AUTOSAR XML (schema 4-2-2)
package /ETAS_BIP_STACKM/SwComponentTypes
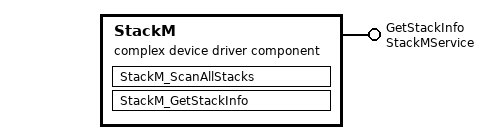
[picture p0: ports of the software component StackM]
  complex device driver sw component type StackM
    provide port GetStackInfo: provided-interface=StackMService
    behavior IntBeh_StackM
      operation invoked event OIE_GetStackInfo: start-on-event=StackM_GetStackInfo, operation=GetStackInfo.GetStackInfo
      runnable StackM_ScanAllStacks
      runnable StackM_GetStackInfo
package /ETAS_BIP_STACKM/SwcImplementations
  swc implementation Impl_StackM: programming-language=C, sw-version=2.0.0, swc-bsw-mapping=SwcBswMapping, vendor-id=11, behavior=IntBeh_StackM
    code-descriptors:
      code CodeDescr_Rtm: artifact-descriptors=autosar-engineering-object={short-label=Code_0, category=SWSRC}
package /ETAS_BIP_STACKM/SwcBswMappings
  swc bsw mapping SwcBswMapping: bsw-behavior=BswInternalBehavior, swc-behavior=IntBeh_StackM
    runnable-mappings:
      bsw-entity=StackM_ScanAllStacks, swc-runnable=StackM_ScanAllStacks
      bsw-entity=StackM_GetStackInfo, swc-runnable=StackM_GetStackInfo
